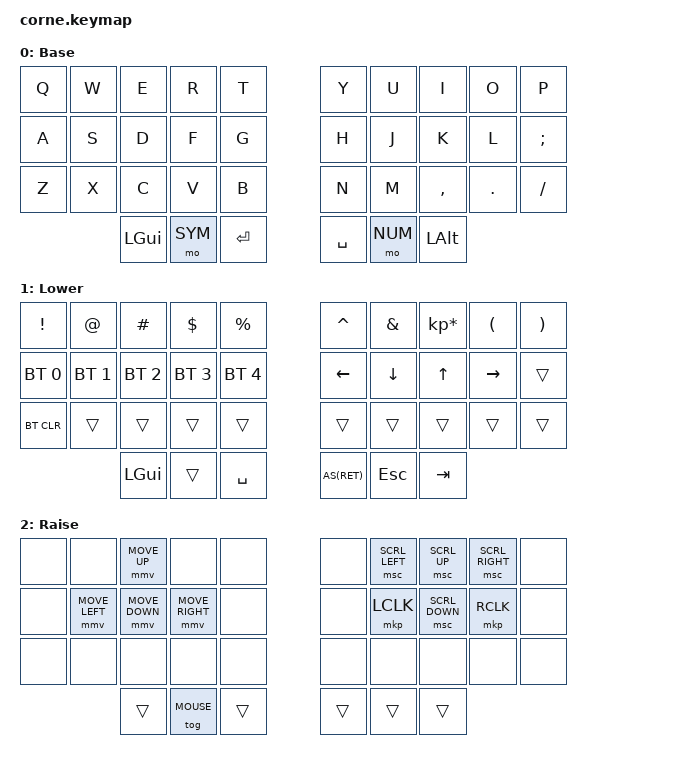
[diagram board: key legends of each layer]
/*
 * Copyright (c) 2020 The ZMK Contributors
 *
 * SPDX-License-Identifier: MIT
 */

#include <behaviors.dtsi>
#include <dt-bindings/zmk/keys.h>
#include <dt-bindings/zmk/bt.h>

/ {
    chosen {
        zmk,physical-layout = &foostan_corne_5col_layout;
    };
    
        keymap {
                compatible = "zmk,keymap";

                default_layer {
// -----------------------------------------------------------------------------------------
// |  Q  |  W  |  E  |  R  |  T  |     |  Y  |  U   |  I   |  O   | P |
// |  A  |  S  |  D  |  F  |  G  |     |  H  |  J   |  K   |  L   | ' | 
// |  Z  |  X  |  C  |  V  |  B  |     |  N  |  M   | CTRL | META | . |
//             | GUI | LWR | SPC |     | ENT | RSE  | BSPC |
                        display-name = "Base";
                        bindings = <
        &kp Q         &kp W         &kp E         &kp R         &kp T             &kp Y         &kp U         &kp I         &kp O         &kp P  
        &kp A         &kp S         &kp D         &kp F         &kp G             &kp H         &kp J         &kp K         &kp L        &kp SEMI 
        &kp Z         &kp X         &kp C         &kp V         &kp B             &kp N         &kp M       &kp COMMA      &kp DOT       &kp FSLH
                                   &kp LGUI      &mo SYM       &kp RET          &kp SPACE      &mo NUM       &kp LALT
                        >;
                };

                lower_layer {
// -----------------------------------------------------------------------------------------
// | !     |  @  |  #  |  $  |  %  |     |  ^  |  &  |  *  |  (  |  )  |
// | BT1   | BT2 | BT3 | BT4 | BT5 |     | LFT | DWN |  UP | RGT |     |
// | BTCLR |     |     |     |     |     |     |     |     |     |     |
//               | GUI |     | SPC |     | ENT | ESC | TAB |
                        display-name = "Lower";
                        bindings = <
   &kp EXCL     &kp AT       &kp HASH     &kp DLLR     &kp PRCNT        &kp CARET &kp AMPS  &kp KP_MULTIPLY &kp LPAR  &kp RPAR
   &bt BT_SEL 0 &bt BT_SEL 1 &bt BT_SEL 2 &bt BT_SEL 3 &bt BT_SEL 4     &kp LEFT  &kp DOWN  &kp UP          &kp RIGHT &trans 
   &bt BT_CLR   &trans       &trans       &trans       &trans           &trans    &trans    &trans          &trans    &trans 
                             &kp LGUI     &trans       &kp SPACE        AS(RET)   &kp ESC   &kp TAB
                        >;
                };

                raise_layer {
// -----------------------------------------------------------------------------------------
// | 1! |  2@ |  3# |  4$ |  5% |     |  6^ |  7& |  8* |  9(  |  0)  |
// | -_ |  =+ |  {  |  [  |  (  |     |  )  |  ]  |  }  |  /?  |  \|  |
// | `~ |     |     |  ,< |  :  |     |  ;  |  .> | CTRL| META |      |
//            | GUI | ESC | SPC |     | ENT |     | TAB |
                        display-name = "Raise";
                        bindings = <

                        &none   &none           &mmv MOVE_UP    &none            &none    &none   &msc SCRL_LEFT  &msc SCRL_UP    &msc SCRL_RIGHT  &none
                        &none   &mmv MOVE_LEFT  &mmv MOVE_DOWN  &mmv MOVE_RIGHT  &none    &none   &mkp LCLK       &msc SCRL_DOWN  &mkp RCLK        &none
                        &none   &none           &none           &none            &none    &none   &none           &none           &none            &none 
                                                &trans          &tog MOUSE       &trans   &trans  &trans          &trans
                        >;
                };

                extra_1 {
                        status = "reserved";
                };

                extra_2 {
                        status = "reserved";
                };

                extra_3 {
                        status = "reserved";
                };
        };
};
